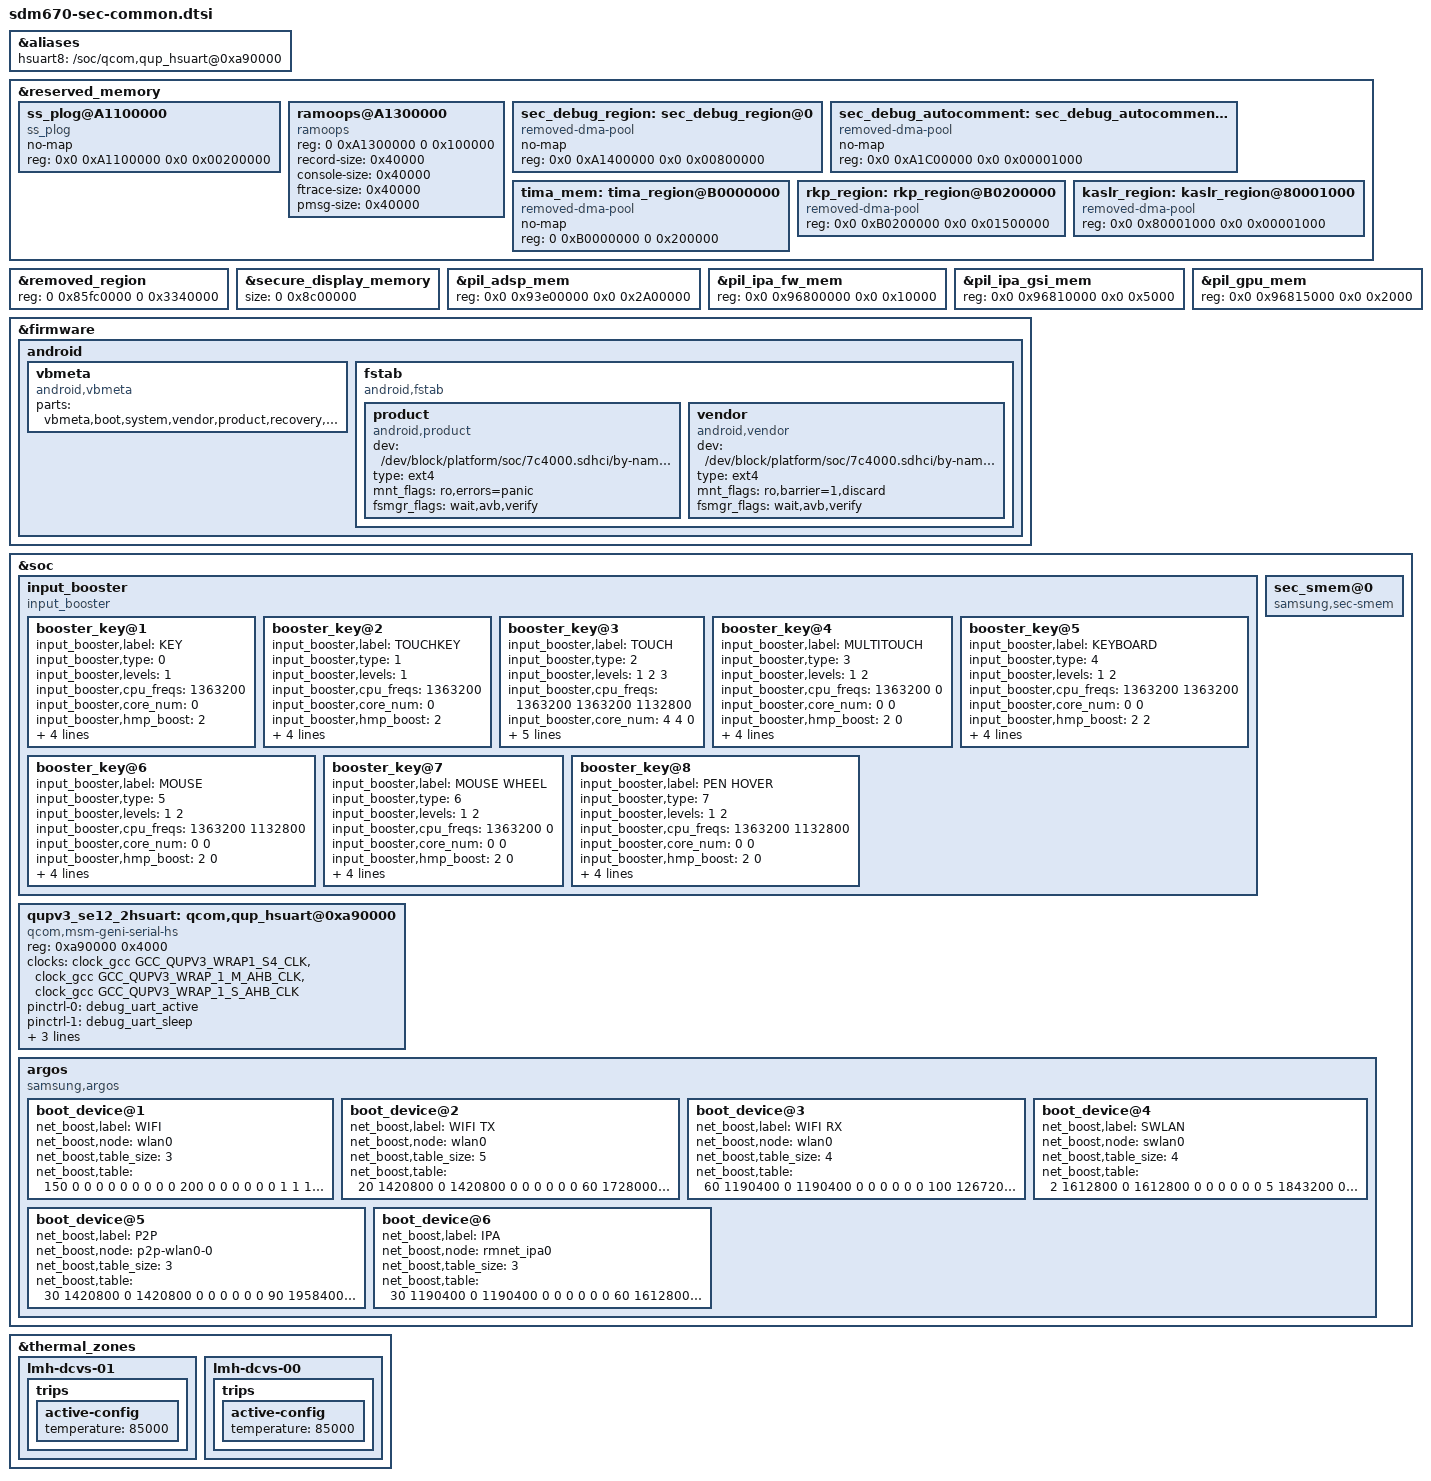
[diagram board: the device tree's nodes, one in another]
/* Copyright (c) 2016-2018, The Linux Foundation. All rights reserved.
 *
 * This program is free software; you can redistribute it and/or modify
 * it under the terms of the GNU General Public License version 2 and
 * only version 2 as published by the Free Software Foundation.
 *
 * This program is distributed in the hope that it will be useful,
 * but WITHOUT ANY WARRANTY; without even the implied warranty of
 * MERCHANTABILITY or FITNESS FOR A PARTICULAR PURPOSE.  See the
 * GNU General Public License for more details.
 */


/{
	/delete-node/qcom,smb1355@8;
	/delete-node/qcom,smb1355@c;
};

&aliases {
	hsuart8 = "/soc/qcom,qup_hsuart@0xa90000";
};

&reserved_memory {
	ss_plog@A1100000 {
		compatible = "ss_plog";
		no-map;
		reg = <0x0 0xA1100000 0x0 0x00200000>;
	};

	ramoops@A1300000 {
		compatible = "ramoops";
		reg = <0 0xA1300000 0 0x100000>;
		record-size = <0x40000>;
		console-size = <0x40000>;
		ftrace-size = <0x40000>;
		pmsg-size = <0x40000>;
	};

	/* CONFIG_SEC_DEBUG reserves 8MB */
	sec_debug_region: sec_debug_region@0 {
		compatible = "removed-dma-pool";
		no-map;
		reg = <0x0 0xA1400000 0x0 0x00800000>;
	};

	sec_debug_autocomment: sec_debug_autocomment@0 {
		compatible = "removed-dma-pool";
		no-map;
		reg = <0x0 0xA1C00000 0x0 0x00001000>;
	};
	
        /*to reserve 2MB for TIMA */
                tima_mem: tima_region@B0000000 {
                compatible = "removed-dma-pool";
                no-map;
                reg = <0 0xB0000000 0 0x200000>;
        };	

	/* rkp_region reserves 21MB for RKP */                          
	rkp_region: rkp_region@B0200000 {                               
			compatible = "removed-dma-pool";                        
			reg = <0x0 0xB0200000 0x0 0x01500000>;                  
	};

	/* Kaslr offset reserve */
	kaslr_region: kaslr_region@80001000 {
		compatible = "removed-dma-pool";
		reg = <0x0 0x80001000 0x0 0x00001000>;
	};
};

&removed_region {
	reg = <0 0x85fc0000 0 0x3340000>;
};

&secure_display_memory {
	size = <0 0x8c00000>;
};

&pil_adsp_mem {
	reg = <0x0 0x93e00000 0x0 0x2A00000>;
};

&pil_ipa_fw_mem {
	reg = <0x0 0x96800000 0x0 0x10000>;
};

&pil_ipa_gsi_mem {
	reg = <0x0 0x96810000 0x0 0x5000>;
};

&pil_gpu_mem {
	reg = <0x0 0x96815000 0x0 0x2000>;
};

&firmware {
	android {
        vbmeta {
            compatible = "android,vbmeta";
            parts = "vbmeta,boot,system,vendor,product,recovery,dtbo,abl,xbl,tz,hyp";
        };
		fstab {
			compatible = "android,fstab";
			product {
				compatible = "android,product";
				dev = "/dev/block/platform/soc/7c4000.sdhci/by-name/product";
				type = "ext4";
				mnt_flags = "ro,errors=panic";
				fsmgr_flags = "wait,avb,verify";
			};

			vendor {
				compatible = "android,vendor";
				dev = "/dev/block/platform/soc/7c4000.sdhci/by-name/vendor";
				type = "ext4";
				mnt_flags = "ro,barrier=1,discard";
				fsmgr_flags = "wait,avb,verify";
			};
		};
	};
};

&soc {
	input_booster {
        status = "okay";
        compatible = "input_booster";
        #address-cells = <1>;
        #size-cells = <0>;

        booster_key@1 {
            input_booster,label = "KEY";
            input_booster,type = <0>;   /* BOOSTER_DEVICE_KEY */

            input_booster,levels = <1>;

            /* Frequency table */
            /* for level    :   1_Head */
            input_booster,cpu_freqs = <1363200>;
            input_booster,core_num = <0>;
            input_booster,hmp_boost = <2>;
            input_booster,bimc_freqs = <0>;
            input_booster,lpm_bias = <0>;

            /* Time table */
            input_booster,head_times = <200>;
            input_booster,tail_times = <0>;
        };
        booster_key@2 {
            input_booster,label = "TOUCHKEY";
            input_booster,type = <1>;   /* BOOSTER_DEVICE_TOUCHKEY */

            input_booster,levels = <1>;

            /* Frequency table */
            /* for level    :   1_Head */
            input_booster,cpu_freqs = <1363200>;
            input_booster,core_num = <0>;
            input_booster,hmp_boost = <2>;
            input_booster,bimc_freqs = <0>;
            input_booster,lpm_bias = <0>;

            /* Time table */
            input_booster,head_times = <0>;
            input_booster,tail_times = <300>;
        };
        booster_key@3 {
            input_booster,label = "TOUCH";
            input_booster,type = <2>;   /* BOOSTER_DEVICE_TOUCH */

            input_booster,levels = <1 2 3>;

            /* Frequency table */
            /* for level    :   1_Head, 2_Head, 2_Tail */
            input_booster,cpu_freqs = <1363200 1363200 1132800>;
            input_booster,core_num = <4 4 0>;
            input_booster,hmp_boost = <2 2 2>;
            input_booster,bimc_freqs = <0 0 0>;
            input_booster,lpm_bias = <5 5 5>;

            /* Time table */
            input_booster,head_times = <200 200 0>;
            input_booster,tail_times = <0 0 300>;
        };
        booster_key@4 { // Input Booster +
            input_booster,label = "MULTITOUCH";
            input_booster,type = <3>;   /* BOOSTER_DEVICE_MULTITOUCH */

            input_booster,levels = <1 2>;

            /* Frequency table */
            /* for level    :   1_Head 2_Tail*/
            input_booster,cpu_freqs = <1363200 0>;
            input_booster,core_num = <0 0>;
            input_booster,hmp_boost = <2 0>;
            input_booster,bimc_freqs = <0 0>;
            input_booster,lpm_bias = <0 0>;

            /* Time table */
            input_booster,head_times = <1000 0>;
            input_booster,tail_times = <0 500>;
        };
        booster_key@5 {
            input_booster,label = "KEYBOARD";
            input_booster,type = <4>;   /* BOOSTER_DEVICE_KEYBOARD */

            input_booster,levels = <1 2>;

            /* Frequency table */
            /* for level    :   1_Head, 2_Tail */
            input_booster,cpu_freqs = <1363200 1363200>;
            input_booster,core_num = <0 0>;
            input_booster,hmp_boost = <2 2>;
            input_booster,bimc_freqs = <0 0>;
            input_booster,lpm_bias = <0 0>;

            /* Time table */
            input_booster,head_times = <130 130>;
            input_booster,tail_times = <0 0>;
        };
        booster_key@6 {
            input_booster,label = "MOUSE";
            input_booster,type = <5>;   /* BOOSTER_DEVICE_MOUSE */

            input_booster,levels = <1 2>;

            /* Frequency table */
            /* for level    :   1_Head 2_Tail*/
            input_booster,cpu_freqs = <1363200 1132800>;
            input_booster,core_num = <0 0>;
            input_booster,hmp_boost = <2 0>;
            input_booster,bimc_freqs = <0 0>;
            input_booster,lpm_bias = <0 0>;

            /* Time table */
            input_booster,head_times = <200 0>;
            input_booster,tail_times = <0 300>;
        };
        booster_key@7 {
            input_booster,label = "MOUSE WHEEL";
            input_booster,type = <6>;   /* BOOSTER_DEVICE_MOUSE */

            input_booster,levels = <1 2>;

            /* Frequency table */
            /* for level    :   1_Head 2_Tail*/
            input_booster,cpu_freqs = <1363200 0>;
            input_booster,core_num = <0 0>;
            input_booster,hmp_boost = <2 0>;
            input_booster,bimc_freqs = <0 0>;
            input_booster,lpm_bias = <0 0>;

            /* Time table */
            input_booster,head_times = <200 0>;
            input_booster,tail_times = <0 0>;
        };
        booster_key@8 {
            input_booster,label = "PEN HOVER";
            input_booster,type = <7>;   /* BOOSTER_DEVICE_MOUSE */

            input_booster,levels = <1 2>;

            /* Frequency table */
            /* for level    :   1_Head 2_Tail*/
            input_booster,cpu_freqs = <1363200 1132800>;
            input_booster,core_num = <0 0>;
            input_booster,hmp_boost = <2 0>;
            input_booster,bimc_freqs = <0 0>;
            input_booster,lpm_bias = <0 0>;

            /* Time table */
            input_booster,head_times = <200 0>;
            input_booster,tail_times = <0 300>;
        }; // Input Booster -
        /* If you need to add new key type, add it this position */
    };
	
	qupv3_se12_2hsuart: qcom,qup_hsuart@0xa90000 {
		compatible = "qcom,msm-geni-serial-hs", "qcom,msm-geni-uart";
		reg = <0xa90000 0x4000>;
		reg-names = "se_phys";
		clock-names = "se-clk", "m-ahb", "s-ahb";
		clocks = <&clock_gcc GCC_QUPV3_WRAP1_S4_CLK>,
			<&clock_gcc GCC_QUPV3_WRAP_1_M_AHB_CLK>,
			<&clock_gcc GCC_QUPV3_WRAP_1_S_AHB_CLK>;
		pinctrl-names = "default", "sleep";
		pinctrl-0 = <&debug_uart_active>;
		pinctrl-1 = <&debug_uart_sleep>;
		interrupts-extended = <&pdc GIC_SPI 357 0>;
		qcom,wrapper-core = <&qupv3_1>;
		status = "ok";
		always-on-clock;
	};
	sec_smem@0 {
		compatible = "samsung,sec-smem";
		status = "okay";
	};

	argos {
		compatible = "samsung,argos";
		#address-cells = <1>;
		/* The device number should be assigned for each device, e.g. "boot_device@1" and "boot_device@2".
		 * Duplicated number is not allowed. Please refer the below example.
		 */

		/* Table Format should be
		 * <Throughput(Mbps) ARM_min ARM_max Little_min Little_max BIMC1 BIMC1 Task IRQ SCHED_boost>
		 * ARM_min : Big Core's minimum frequency lock. 0 means not set,
		 * ARM_max : Big Core's maximum frequency lock. 0 means not set,
		 * Little_min : Little Core's minimum frequency lock. 0 means not set,
		 * Little_max : Little Core's maximum frequency lock. 0 means not set,
		 * BIMC1 : Memory frequency lock. 0 means not set,(not used now)
		 * BIMC2 : Memory frequency lock. 0 means not set, (not used now)
		 * Task : 1 - Set task affinity lock.
		 *	0 - Not set or unlock,
		 *		Task affinity should be predefined driver's code.
		 * IRQ : 1 - Set irq affinity lock.
		 *       0 - Not set or unlock,
		 *		Task affinity should be predefined driver's code.
		 * SCHED_boost : 1 - Increase sched boosting count (not used now)
		 *             0 - Decrease sched boosting count
		 */
		/*
		 *boot_device@1 {
		 *		net_boost,label="WIFI";
		 *		net_boost,node="wlan0";
		 *		net_boost,table_size = <3>;
		 *		net_boost,table= <
		 *			5  2016000 0 2016000 0 0 0 0 0 0
		 *			10  2016000 0 2016000 0 0 0 0 0 0
		 *			20  2016000 0 2016000 0 0 0 0 0 0
		 *			30  2016000 0 2016000 0 0 0 0 0 0
		 *			>;
		 * };
		 */
		boot_device@1 {
			net_boost,label="WIFI";
			net_boost,node="wlan0";
			net_boost,table_size = <3>;
			net_boost,table= <
				150 0 0 0 0 0 0 0 0 0
				200 0 0 0 0 0 0 1 1 1
				300 0 0 0 0 0 0 1 1 1
				>;
		};
		boot_device@2 {
			net_boost,label="WIFI TX";
			net_boost,node="wlan0";
			net_boost,table_size = <5>;
			net_boost,table= <
				20 1420800 0 1420800 0 0 0 0 0 0
				60 1728000 0 1728000 0 0 0 0 0 0
				100 1958400 0 1958400 0 0 0 0 0 0
				150 2208000 0 2208000 0 0 0 1 1 1
				300 2649600 0 2649600 0 0 0 1 1 1
				>;
		};
		boot_device@3 {
			net_boost,label="WIFI RX";
			net_boost,node="wlan0";
			net_boost,table_size = <4>;
			net_boost,table= <
				60 1190400 0 1190400 0 0 0 0 0 0
				100 1267200 0 1267200 0 0 0 0 0 0
				200 1728000 0 1728000 0 0 0 1 1 1
				300 2035200 0 2035200 0 0 0 1 1 1
				>;
		};
		boot_device@4 {
			net_boost,label="SWLAN";
			net_boost,node="swlan0";
			net_boost,table_size = <4>;
			net_boost,table= <
				2 1612800 0 1612800 0 0 0 0 0 0
				5 1843200 0 1843200 0 0 0 0 0 0
				20 2092800 0 2092800 0 0 0 1 1 1
				50 2246400 0 2246400 0 0 0 1 1 1
				>;
		};
		boot_device@5 {
			net_boost,label="P2P";
			net_boost,node="p2p-wlan0-0";
			net_boost,table_size = <3>;
			net_boost,table= <
				30 1420800 0 1420800 0 0 0 0 0 0
				90 1958400 0 1958400 0 0 0 0 0 0
				300 2208000 0 2208000 0 0 0 1 1 1
				>;
		};
		boot_device@6 {
			net_boost,label="IPA";
			net_boost,node="rmnet_ipa0";
			net_boost,table_size = <3>;
			net_boost,table= <
				30 1190400 0 1190400 0 0 0 0 0 0
				60 1612800 0 1612800 0 0 0 0 0 0
				100 1708800 0 1708800 0 0 0 1 1 1
				>;
		};
	};
};

&thermal_zones {
	lmh-dcvs-01 {
		trips {
			active-config {
				temperature = <85000>;
			};
		};
	};

	lmh-dcvs-00 {
		trips {
			active-config {
				temperature = <85000>;
			};
		};
	};
};

